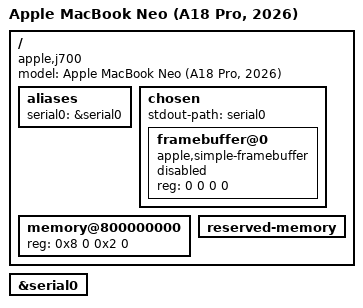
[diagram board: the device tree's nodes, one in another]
// SPDX-License-Identifier: GPL-2.0+ OR MIT
/*
 * Apple MacBook Neo (A18 Pro, 2026)
 *
 * target-type: J700
 *
 * Copyright The Asahi Linux Contributors
 */

/dts-v1/;

#include "t8140.dtsi"

/ {
	compatible = "apple,j700", "apple,t8140", "apple,arm-platform";
	model = "Apple MacBook Neo (A18 Pro, 2026)";

	aliases {
		serial0 = &serial0;
	};

	chosen {
		ranges;
		#address-cells = <2>;
		#size-cells = <2>;

		stdout-path = "serial0";

		framebuffer@0 {
			compatible = "apple,simple-framebuffer",
			             "simple-framebuffer";
			reg = <0 0 0 0>; /* To be filled by loader */
			/* Format properties will be added by loader */

			status = "disabled";
		};
	};

	memory@800000000 {
		device_type = "memory";
		reg = <0x8 0 0x2 0>; /* To be filled by loader */
	};

	reserved-memory {
		ranges;
		#address-cells = <2>;
		#size-cells = <2>;
		/* To be filled by loader */
	};
};

&serial0 {
	status = "okay";
};
